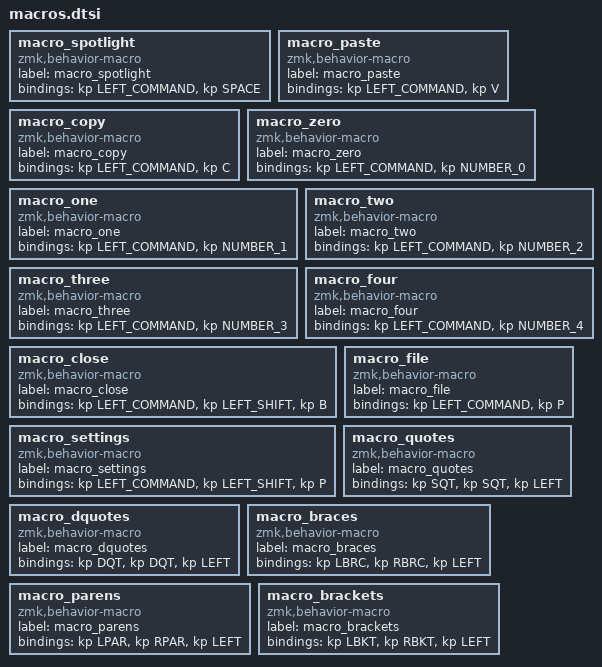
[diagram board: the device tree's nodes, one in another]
macro_spotlight: macro_spotlight{
compatible = "zmk,behavior-macro";
label = "macro_spotlight";
#binding-cells = <0>;
bindings = <&kp LEFT_COMMAND>, <&kp SPACE>;
};
macro_paste: macro_paste{
compatible = "zmk,behavior-macro";
label = "macro_paste";
#binding-cells = <0>;
bindings = <&kp LEFT_COMMAND>, <&kp V>;
};
macro_copy: macro_copy{
compatible = "zmk,behavior-macro";
label = "macro_copy";
#binding-cells = <0>;
bindings = <&kp LEFT_COMMAND>, <&kp C>;
};
macro_zero: macro_zero{
compatible = "zmk,behavior-macro";
label = "macro_zero";
#binding-cells = <0>;
bindings = <&kp LEFT_COMMAND>, <&kp NUMBER_0>;
};
macro_one: macro_one{
compatible = "zmk,behavior-macro";
label = "macro_one";
#binding-cells = <0>;
bindings = <&kp LEFT_COMMAND>, <&kp NUMBER_1>;
};
macro_two: macro_two{
compatible = "zmk,behavior-macro";
label = "macro_two";
#binding-cells = <0>;
bindings = <&kp LEFT_COMMAND>, <&kp NUMBER_2>;
};
macro_three: macro_three{
compatible = "zmk,behavior-macro";
label = "macro_three";
#binding-cells = <0>;
bindings = <&kp LEFT_COMMAND>, <&kp NUMBER_3>;
};
macro_four: macro_four{
compatible = "zmk,behavior-macro";
label = "macro_four";
#binding-cells = <0>;
bindings = <&kp LEFT_COMMAND>, <&kp NUMBER_4>;
};
macro_close: macro_close{
compatible = "zmk,behavior-macro";
label = "macro_close";
#binding-cells = <0>;
bindings = <&kp LEFT_COMMAND>, <&kp LEFT_SHIFT>, <&kp B>;
};
macro_file: macro_file{
compatible = "zmk,behavior-macro";
label = "macro_file";
#binding-cells = <0>;
bindings = <&kp LEFT_COMMAND>, <&kp P>;
};
macro_settings: macro_settings{
compatible = "zmk,behavior-macro";
label = "macro_settings";
#binding-cells = <0>;
bindings = <&kp LEFT_COMMAND>, <&kp LEFT_SHIFT>, <&kp P>;
};
macro_quotes: macro_quotes{
compatible = "zmk,behavior-macro";
label = "macro_quotes";
#binding-cells = <0>;
bindings = <&kp SQT>, <&kp SQT>, <&kp LEFT>;
};
macro_dquotes: macro_dquotes{
compatible = "zmk,behavior-macro";
label = "macro_dquotes";
#binding-cells = <0>;
bindings = <&kp DQT>, <&kp DQT>, <&kp LEFT>;
};
macro_braces: macro_braces{
compatible = "zmk,behavior-macro";
label = "macro_braces";
#binding-cells = <0>;
bindings = <&kp LBRC>, <&kp RBRC>, <&kp LEFT>;
};
macro_parens: macro_parens{
compatible = "zmk,behavior-macro";
label = "macro_parens";
#binding-cells = <0>;
bindings = <&kp LPAR>, <&kp RPAR>, <&kp LEFT>;
};
macro_brackets: macro_brackets{
compatible = "zmk,behavior-macro";
label = "macro_brackets";
#binding-cells = <0>;
bindings = <&kp LBKT>, <&kp RBKT>, <&kp LEFT>;
};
